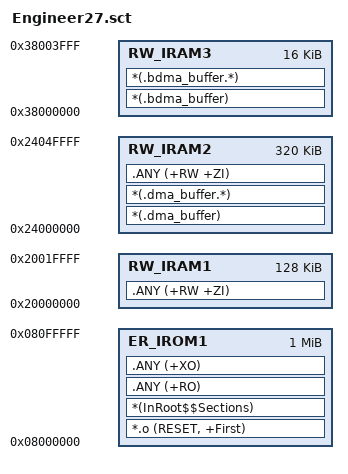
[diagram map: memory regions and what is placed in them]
; *************************************************************
; *** Scatter file for Engineer27 (STM32H723VGTx)
; ***
; *** Equivalent to the GCC linker script STM32H723xG_flash.ld:
; ***   .data/.bss      -> DTCMRAM (0x20000000, 128K)
; ***   .dma_buffer     -> AXI SRAM / RAM_D1 (0x24000000, DMA reachable)
; *** DTCM is NOT reachable by any DMA on STM32H7, so buffers used by
; *** DMA must stay out of the .ANY (+RW +ZI) of RW_IRAM1.
; *************************************************************

LR_IROM1 0x08000000 0x00100000  {    ; load region size_region
  ER_IROM1 0x08000000 0x00100000  {  ; load address = execution address
   *.o (RESET, +First)
   *(InRoot$$Sections)
   .ANY (+RO)
   .ANY (+XO)
  }
  RW_IRAM1 0x20000000 0x00020000  {  ; DTCMRAM 128K
   .ANY (+RW +ZI)
  }
  RW_IRAM2 0x24000000 0x00050000  {  ; AXI SRAM (RAM_D1) 320K, DMA reachable
   *(.dma_buffer)
   *(.dma_buffer.*)
   .ANY (+RW +ZI)
  }
  RW_IRAM3 0x38000000 0x00004000  {  ; SRAM4 (RAM_D3) 16K, reachable by BDMA only
   *(.bdma_buffer)
   *(.bdma_buffer.*)
  }
}
